# RTS591x register map
Vendor: Realtek Semiconductor Corp.; Series: RTS591x Series; File version: 1.0
CPU: ARMV8MML r0p0, little endian, MPU, FPU, VTOR, 3 interrupt priority bits, 4 SAU regions
Registers are 32-bit, read-write, reset 0x0 unless marked. A register's access mark holds for its fields unless they carry their own. Offsets are from the block's base; [hi:lo] are bit positions; {n}, {i} and the like mark numbered series; 'fields as' and 'values as' point back to an identical list.

## I2C0 — I2C Controller
Base 0x4000D000
Same registers: I2C1 0x4000D200, I2C2 0x4000D400, I2C3 0x4000D600, I2C4 0x4000D800, I2C5 0x4000DA00, I2C6 0x4000DC00, I2C7 0x4000DE00
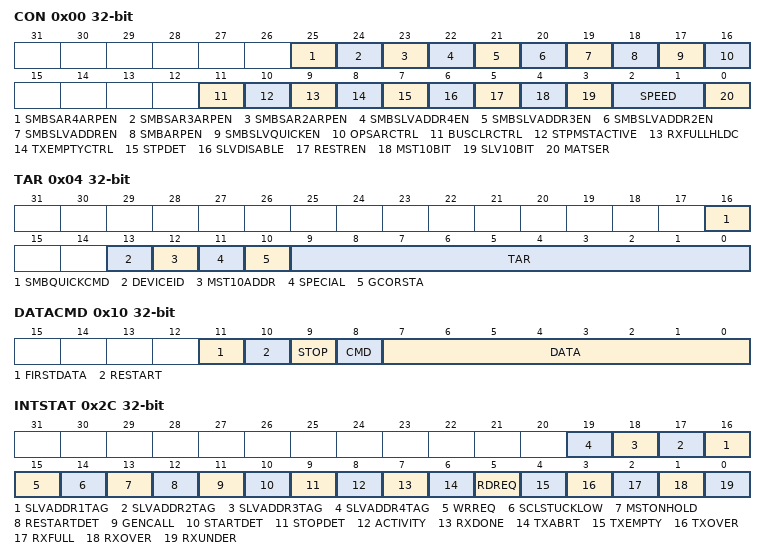
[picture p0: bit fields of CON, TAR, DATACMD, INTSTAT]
0x00 CON — CONTROL REGISTER
  [25] SMBSAR4ARPEN — Enabled ARP Control Or Not
    0=Disable (SMBus ARP control is disabled); 1=Enable (SMBus ARP control is enabled)
  [24] SMBSAR3ARPEN — Enabled ARP Control Or Not
    0=DISABLE (SMBus ARP control is disabled); 1=ENABLE (SMBus ARP control is enabled)
  [23] SMBSAR2ARPEN — Enabled ARP Control Or Not
    values as SMBSAR3ARPEN
  [22] SMBSLVADDR4EN — SMBus Persistent Slave address(SAR4) Control Is Enabled Or Not
    0=DISABLE (SMBus Persistent Slave address(SAR4) control is disabled); 1=ENABLE (SMBus Persistent Slave address(SAR4) control is enabled)
  [21] SMBSLVADDR3EN — SMBus Persistent Slave Address(SAR3) Control Is Enabled Or Not
    0=DISABLE (SMBus Persistent Slave address(SAR3) control is disabled); 1=ENABLE (SMBus Persistent Slave address(SAR3) control is enabled)
  [20] SMBSLVADDR2EN — SMBus Persistent Slave Address(SAR2) Control Is Enabled Or Not
    0=DISABLE (SMBus Persistent Slave address(SAR2) control is disabled); 1=ENABLE (SMBus Persistent Slave address(SAR2) control is enabled)
  [19] SMBSLVADDREN — SMBus Persistent Slave Address Control Is Enabled Or Not
    0=DISABLE (SMBus Persistent Slave address control is disabled); 1=ENABLE (SMBus Persistent Slave address control is enabled)
  [18] SMBARPEN — Enabled ARP Control Or Not
    values as SMBSAR3ARPEN
  [17] SMBSLVQUICKEN — Receive Quick Command Or Not
    0=DISABLE (SMBus Slave is disabled to receive Quick command); 1=ENABLE (SMBus Slave is enabled to receive Quick command)
  [16] OPSARCTRL — Enables the Usage of IC_OPTIONAL_SAR
    0=DISABLE (Optional SAR Address Register is disabled); 1=ENABLE (Optional SAR Address Register is enabled)
  [11] BUSCLRCTRL — Enables the Bus Clear Feature
    0=DISABLE (Bus Clear Feature is enabled); 1=ENABLE (Bus Clear Feature is disabled)
  [10] STPMSTACTIVE — How I2c Controller Issues The Stop Detection Interrupt
    0=DISABLE (Master issues the stop detection interrupt irrespective of whether master is active or not); 1=ENABLE (Master issues the stop detection interrupt only when master is active)
  [9] RXFULLHLDC — Hold the Bus When The Rx FIFO Is Full Or Not
    0=DISABLE (Overflow when RX FIFO is full); 1=ENABLE (Hold bus when RX FIFO is full)
  [8] TXEMPTYCTRL — Controls the Generation Of The Tx Empty Interrupt
    0=DISABLE (Default behaviour of tx empty interrupt); 1=ENABLE (Controlled generation of tx empty interrupt)
  [7] STPDET — How Slave Issues Stop Detection Interrupt
    0=ALWAYS (Slave issues stop detection interrupt always); 1=ADDRESSED (Slave issues stop detection interrupt only if addressed)
  [6] SLVDISABLE — Enable/Disable Slave Mode
    0=Enable slave mode; 1=Disable slave mode
  [5] RESTREN — Enable/Disable Master Restart
    0=DISABLE (Master restart disabled); 1=ENABLE (Master restart enabled)
  [4] MST10BIT — Master Is 7-bit Or 10-bit Addressing Mode
    0=7_BIT (Master 7-bit addressing); 1=10_BIT (Master 10-bit addressing)
  [3] SLV10BIT — Slave Responds To 7-bit Or 10-bit Addresses
    0=7_BIT (Slave 7-bit addressing); 1=10_BIT (Slave 10-bit addressing)
  [2:1] SPEED — Speed Mode
    0=NONE (Not defined); 1=STANDARD (Standard Speed mode of operation); 2=FAST (Fast or Fast Plus mode of operation); 3=HIGH (High Speed mode of operation)
  [0] MATSER — Enable/Disable Master Mode
    0=DISABLE (Master mode is disabled); 1=ENABLE (Master mode is enabled)
0x04 TAR — TARGET ADDRESS REGISTER
  [16] SMBQUICKCMD — Indicates Whether A Quick Command Is To Be Performed
    0=DISABLE (Disables programming of QUICK-CMD transmission); 1=ENABLE (Enables programming of QUICK-CMD transmission)
  [13] DEVICEID — Programming of DEVICE-ID Transmission
    0=DISABLE (Disables programming of DEVICE-ID transmission); 1=ENABLE (Enables programming of DEVICE-ID transmission)
  [12] MST10ADDR — Control Starts Transfers In 7-bit Or 10-bit Addressing Mode
    0=7_BIT (Address 7-bit transmission format); 1=10_BIT (Address 10-bit transmission format)
  [11] SPECIAL — Indicates Whether Software Performs A Device-id Or General Call Or Start Byte Command
    0=DISABLE (Disables programming of GENERAL_CALL or START_BYTE transmission); 1=ENABLE (Enables programming of GENERAL_CALL or START_BYTE transmission)
  [10] GCORSTA — Indicates Whether A General Call Or Start Byte Command
    0=GEN_CALL (General Call byte transmission); 1=START (START byte transmission)
  [9:0] TAR — Target Address For Any Master Transaction
0x08 SAR — SLAVE ADDRESS REGISTER
  [9:0] SAR — Holds The Slave Address When The I2c Is Operating As A Slave
0x0C HSMADDR — HIGH SPEED MASTER MODE CODE ADDRESS REGISTER
  [2:0] HSMAR — Holds The Value Of The I2C HS Mode Master Code
0x10 DATACMD — DATA BUFFER AND COMMAND REGISTER
  [11] FIRSTDATA ro — Indicates The First Data Byte Received After The Address Phase
    0=INACTIVE (Non sequential data byte received); 1=ACTIVE (Sequential data byte received)
  [10] RESTART wo — Controls Whether a RESTART Is Issued Before The Byte Is Sent Or Received
    0=DISABLE (Do not Issue RESTART before this command); 1=ENABLE (Issue RESTART before this command)
  [9] STOP wo — Controls Whether A Stop Is Issued After The Byte Is Sent Or Received
    0=DISABLE (Do not issue STOP after this command); 1=ENABLE (Issue STOP after this command)
  [8] CMD wo — Controls Whether A Read Or A Write Is Performed
    0=WRITE (Master write command); 1=READ (Master read command)
  [7:0] DATA — The Data To Be Transmitted Or Received On The I2C Bus
0x14 SCLHCNT — STANDARD SPEED I2C CLOCK SCL HIGH COUNT REGISTER
  [15:0] HCNT — Sets the SCL Clock High-period Count For Standard Speed
0x14 UFMSCLHCNT (alternate view of SCLHCNT) — ULTRA-FAST SPEED I2C CLOCK SCL HIGH COUNT REGISTER
  [15:0] UFMHCNT — Sets the SCL Clock High-period Count For Ultra-Fast Speed
0x18 SCLLCNT — STANDARD SPEED I2C CLOCK SCL LOW COUNT REGISTER
  [15:0] LCNT — Sets the SCL Clock Low-period Count For Standard Speed
0x18 UFMSCLLCNT (alternate view of SCLLCNT) — ULTRA-FAST I2C CLOCK SCL LOW COUNT REGISTER
  [15:0] UFMLCNT — Sets the SCL Clock Low-period Count For Ultra-Fast Speed
0x1C FSSCLHCNT — FAST MODE SCL HIGH COUNT REGISTER
  [15:0] HCNT — Sets the SCL Clock High-period Count For Fast Speed
0x1C UFMTBUFCNT (alternate view of FSSCLHCNT) — ULTRA-FAST SPEED MODE TBUF IDLE COUNT REGISTER
  [15:0] TBUFCNT — Sets the Bus-Free time between a STOP and STOP condition count for Ultra-Fast speed
0x20 FSSCLLCNT — FAST MODE SCL LOW COUNT REGISTER
  [15:0] LCNT — Sets the SCL Clock Low-period Count For Fast Speed
0x24 HSSCLHCNT — HIGH SPEED SCL HIGH COUNT REGISTER
  [15:0] HCNT — Sets the SCL Clock High-period Count For High Speed
0x28 HSSCLLCNT — HIGH SPEED SCL LOW COUNT REGISTER
  [15:0] LCNT — Sets the SCL clock low-period count for high speed
0x2C INTSTAT ro — I2C INTERRUPT STATUS REGISTER
  [n+15] SLVADDR{n}TAG (n=1..4) — SLV_ADDR{n}_TAG Interrupt
    0=INACTIVE (SLV_ADDR{n}_TAG interrupt is inactive); 1=ACTIVE (SLV_ADDR{n}_TAG interrupt is active)
  [15] WRREQ — WR_REQ Interrupt
    0=INACTIVE (WR_REQ interrupt is inactive); 1=ACTIVE (WR_REQ interrupt is active)
  [14] SCLSTUCKLOW — SCL_STUCK_AT_LOW Interrupt
    0=INACTIVE (SCL_STUCK_AT_LOW interrupt is inactive); 1=ACTIVE (SCL_STUCK_AT_LOW interrupt is active)
  [13] MSTONHOLD — MASTER_ON_HOLD Interrupt
    0=INACTIVE (MASTER_ON_HOLD interrupt is inactive); 1=ACTIVE (MASTER_ON_HOLD interrupt is active)
  [12] RESTARTDET — RESTART_DET Interrupt
    0=INACTIVE (RESTART_DET interrupt is inactive); 1=ACTIVE (RESTART_DET interrupt is active)
  [11] GENCALL — GEN_CALL Interrupt
    0=INACTIVE (GEN-CALL interrupt is inactive); 1=ACTIVE (GEN-CALL interrupt is active)
  [10] STARTDET — START_DET Interrupt
    0=INACTIVE (START_DET interrupt is inactive); 1=ACTIVE (START_DET interrupt is active)
  [9] STOPDET — STOP_DET Interrupt
    0=INACTIVE (STOP_DET interrupt is inactive); 1=ACTIVE (STOP_DET interrupt is active)
  [8] ACTIVITY — ACTIVITY Interrupt
    0=INACTIVE (ACTIVITY interrupt is inactive); 1=ACTIVE (ACTIVITY interrupt is active)
  [7] RXDONE — RX_DONE Interrupt
    0=INACTIVE (RX_DONE interrupt is inactive); 1=ACTIVE (RX_DONE interrupt is active)
  [6] TXABRT — TX_ABRT Interrupt
    0=INACTIVE (TX_ABRT interrupt is inactive); 1=ACTIVE (TX_ABRT interrupt is active)
  [5] RDREQ — RD_REQ interrupt
    0=INACTIVE (RD_REQ interrupt is inactive); 1=ACTIVE (RD_REQ interrupt is active)
  [4] TXEMPTY — TX_EMPTY Interrupt
    0=INACTIVE (TX_EMPTY interrupt is inactive); 1=ACTIVE (TX_EMPTY interrupt is active)
  [3] TXOVER — TX_OVER Interrupt
    0=INACTIVE (TX_OVER interrupt is inactive); 1=ACTIVE (TX_OVER interrupt is active)
  [2] RXFULL — RX_FULL Interrupt
    0=INACTIVE (RX_FULL interrupt is inactive); 1=ACTIVE (RX_FULL interrupt is active)
  [1] RXOVER — RX_OVER Interrupt
    0=INACTIVE (RX_OVER interrupt is inactive); 1=ACTIVE (RX_OVER interrupt is active)
  [0] RXUNDER — RX_UNDER Interrupt
    0=INACTIVE (RX_UNDER interrupt is inactive); 1=ACTIVE (RX_UNDER interrupt is active)
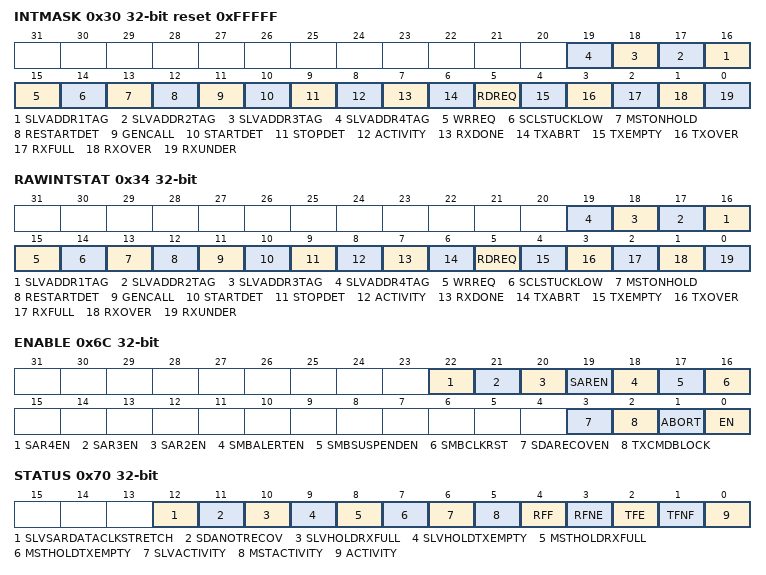
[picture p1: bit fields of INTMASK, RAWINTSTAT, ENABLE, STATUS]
0x30 INTMASK reset 0xFFFFF — INTERRUPT MASK REGISTER
  [n+15] SLVADDR{n}TAG (n=1..4) — SLV_ADDR{n}_TAG Interrupt Mask
    1=UNMASKED (SLV_ADDR{n}_TAG interrupt is unmasked); 0=MASKED (SLV_ADDR{n}_TAG interrupt is masked)
  [15] WRREQ — WR_REQ Interrupt Mask
    1=UNMASKED (WR_REQ interrupt is unmasked); 0=MASKED (WR_REQ interrupt is masked)
  [14] SCLSTUCKLOW — SCL_STUCK_AT_LOW Interrupt Mask
    1=UNMASKED (SCL_STUCK_AT_LOW interrupt is unmasked); 0=MASKED (SCL_STUCK_AT_LOW interrupt is masked)
  [13] MSTONHOLD — MASTER_ON_HOLD Interrupt Mask
    1=UNMASKED (MASTER_ON_HOLD interrupt is unmasked); 0=MASKED (MASTER_ON_HOLD interrupt is masked)
  [12] RESTARTDET — RESTART_DET Interrupt Mask
    1=UNMASKED (RESTART_DET interrupt is unmasked); 0=MASKED (RESTART_DET interrupt is masked)
  [11] GENCALL — GEN_CALL Interrupt Mask
    1=UNMASKED (GEN-CALL interrupt is unmasked); 0=MASKED (GEN-CALL interrupt is masked)
  [10] STARTDET — START_DET Interrupt Mask
    1=UNMASKED (START_DET interrupt is unmasked); 0=MASKED (START_DET interrupt is masked)
  [9] STOPDET — STOP_DET Interrupt Mask
    1=UNMASKED (STOP_DET interrupt is unmasked); 0=MASKED (STOP_DET interrupt is masked)
  [8] ACTIVITY — ACTIVITY Interrupt Mask
    1=UNMASKED (ACTIVITY interrupt is unmasked); 0=MASKED (ACTIVITY interrupt is masked)
  [7] RXDONE — RX_DONE Interrupt Mask
    1=UNMASKED (RX_DONE interrupt is unmasked); 0=MASKED (RX_DONE interrupt is masked)
  [6] TXABRT — TX_ABRT Interrupt Mask
    1=UNMASKED (TX_ABRT interrupt is unmasked); 0=MASKED (TX_ABRT interrupt is masked)
  [5] RDREQ — RD_REQ Interrupt Mask
    1=UNMASKED (RD_REQ interrupt is unmasked); 0=MASKED (RD_REQ interrupt is masked)
  [4] TXEMPTY — TX_EMPTY Interrupt Mask
    1=UNMASKED (TX_EMPTY interrupt is unmasked); 0=MASKED (TX_EMPTY interrupt is masked)
  [3] TXOVER — TX_OVER Interrupt Mask
    1=UNMASKED (TX_OVER interrupt is unmasked); 0=MASKED (TX_OVER interrupt is masked)
  [2] RXFULL — RX_FULL Interrupt Mask
    1=UNMASKED (RX_FULL interrupt is unmasked); 0=MASKED (RX_FULL interrupt is masked)
  [1] RXOVER — RX_OVER Interrupt Mask
    1=UNMASKED (RX_OVER interrupt is unmasked); 0=MASKED (RX_OVER interrupt is masked)
  [0] RXUNDER — RX_UNDER Interrupt Mask
    1=UNMASKED (RX_UNDER interrupt is unmasked); 0=MASKED (RX_UNDER interrupt is masked)
0x34 RAWINTSTAT — INTERRUPT STATUS REGISTER
  [n+15] SLVADDR{n}TAG ro (n=1..4) — SLV_ADDR{n}_TAG Interrupt Status
    values as INTSTAT.SLVADDR1TAG
  [15] WRREQ ro — WR_REQ Interrupt Status
    values as INTSTAT.WRREQ
  [14] SCLSTUCKLOW ro — SCL_STUCK_AT_LOW Interrupt Status
    values as INTSTAT.SCLSTUCKLOW
  [13] MSTONHOLD ro — MASTER_ON_HOLD Interrupt Status
    values as INTSTAT.MSTONHOLD
  [12] RESTARTDET ro — RESTART_DET Interrupt Status
    values as INTSTAT.RESTARTDET
  [11] GENCALL ro — GEN_CALL Interrupt Status
    values as INTSTAT.GENCALL
  [10] STARTDET ro — START_DET Interrupt Status
    values as INTSTAT.STARTDET
  [9] STOPDET ro — STOP_DET Interrupt Status
    values as INTSTAT.STOPDET
  [8] ACTIVITY ro — I2C Controller Activity
    0=INACTIVE (RAW_INTR_ACTIVITY interrupt is inactive); 1=ACTIVE (RAW_INTR_ACTIVITY interrupt is active)
  [7] RXDONE ro — RX_DONE Interrupt Status
    values as INTSTAT.RXDONE
  [6] TXABRT ro — TX_ABRT Interrupt Status
    values as INTSTAT.TXABRT
  [5] RDREQ ro — RD_REQ Interrupt Status
    values as INTSTAT.RDREQ
  [4] TXEMPTY ro — TX_EMPTY Interrupt Status
    values as INTSTAT.TXEMPTY
  [3] TXOVER ro — TX_OVER Interrupt Status
    values as INTSTAT.TXOVER
  [2] RXFULL ro — RX_UNDER Interrupt Status
    values as INTSTAT.RXFULL
  [1] RXOVER ro — RX_UNDER Interrupt Status
    values as INTSTAT.RXOVER
  [0] RXUNDER ro — RX_UNDER Interrupt Status
    values as INTSTAT.RXUNDER
0x38 RXTL — I2C RECEIVE FIFO THRESHOLD REGISTER
  [7:0] THRES — Receive FIFO Threshold Level
0x3C TXTL — I2C TRANSMIT FIFO THRESHOLD REGISTER
  [7:0] THRES — Transmit FIFO Threshold Level
0x40 CLRINT ro — CLEAR COMBINED AND INDIVIDUAL INTERRUPT REGISTER
0x44 CLRRXUNDER ro — Clear RX_UNDER Interrupt
0x48 CLRRXOVER ro — Clear RX_OVER Interrupt Register
0x4C CLRTXOVER ro — Clear TX_OVER Interrupt Register
0x50 CLRRDREQ ro — Clear RD_REQ Interrupt Register
0x54 CLRTXABRT ro — Clear TX_ABRT Interrupt Register
0x58 CLRRXDONE ro — Clear RX_DONE Interrupt Register
0x5C CLRACTIVITY ro — Clear ACTIVITY Interrupt Register
0x60 CLRSTOPDET ro — Clear STOP_DET Interrupt Register
0x64 CLRSTARTDET ro — Clear START_DET Interrupt Register
0x68 CLRGENCALL ro — Clear GEN_CALL Interrupt Register
0x6C ENABLE
  [22] SAR4EN — Controls Whether the SAR4 is Enabled
    0=DISABLE (SAR4 is disabled); 1=ENABLE (SAR4 is enabled)
  [21] SAR3EN — Controls Whether the SAR3 is Enabled
    0=DISABLE (SAR3 is disabled); 1=ENABLE (SAR3 is enabled)
  [20] SAR2EN — Controls Whether the SAR2 is Enabled
    0=DISABLE (SAR2 is disabled); 1=ENABLE (SAR2 is enabled)
  [19] SAREN — Controls Whether the SAR is Enabled
    0=DISABLE (SAR is disabled); 1=ENABLE (SAR is enabled)
  [18] SMBALERTEN — Control Assertion of SMBALERT Signal
    0=DISABLE (Slave will not initates the Alert signal to indicate SMBus Host.); 1=ENABLE (Slave initates the Alert signal to indicate SMBus Host)
  [17] SMBSUSPENDEN — SMBSUS Suspend Mode
    0=DISABLE (Host/Master will not initates the SMBUS system to enter Suspend Mode); 1=ENABLE (Host/Master initates the SMBUS system to enter Suspend Mode)
  [16] SMBCLKRST — SMBus Master Clock Reset
    0=DISABLE (Master will not initates SMBUS Clock Reset Mechanism); 1=ENABLE (Master initates the SMBUS Clock Reset Mechanism)
  [3] SDARECOVEN — Control Knob To Initiate The SDA Recovery Mechanism
    0=DISABLE (Master disabled the SDA stuck at low recovery mechanism); 1=ENABLE (Master initiates the SDA stuck at low recovery mechanism)
  [2] TXCMDBLOCK — Blocks The Transmission Of Data On I2c Bus Or Not
    0=DISABLE (The transmission of data starts on I2C bus automatically); 1=ENABLE (Blocks the transmission of data on I2C bus even if Tx FIFO has data to transmit)
  [1] ABORT — Initiates The Transfer Abort
    0=DISABLE (ABORT operation not in progress); 1=ENABLE (ABORT operation in progress)
  [0] EN — Controls Whether The I2C Controller Is Enabled
    0=DISABLE (Disables I2C controller); 1=ENABLE (Enable I2C controller)
0x70 STATUS ro — I2C STATUS Register
  [12] SLVSARDATACLKSTRETCH — Indicates The Bus Hold (clock Stretching) In Slave Mode With Multiple SAR Feature
    0=Inactive (Slave is not holding the bus to isolate current RX FIFO data from next transfer related to another slave address); 1=Active (Slave holds the bus to isolate current RX FIFO data from next transfer related to another slave address)
  [11] SDANOTRECOV — Indicates That SDA Stuck At Low Is Not Recovered After The Recovery Mechanism
    0=Inactive (SDA Stuck at low is recovered after recovery mechanism); 1=Active (SDA Stuck at low is not recovered after recovery mechanism)
  [10] SLVHOLDRXFULL — Indicates The Bus Hold In Slave Mode Due To Rx FIFO Is Full And Additional Byte Has Been Received
    0=Inactive (Slave is not holding the bus or Bus hold is not due to Rx FIFO is full); 1=Active (Slave holds the bus due to Rx FIFO is full)
  [9] SLVHOLDTXEMPTY — Indicates The Bus Hold In Slave Mode Due To Rx FIFO Is Full And Additional Byte Has Been Received
    0=INACTIVE (Slave is not holding the bus or Bus hold is not due to Rx FIFO is full); 1=ACTIVE (Slave holds the bus due to Rx FIFO is full)
  [8] MSTHOLDRXFULL — INdicates The Bus Hold In Master Mode Due To Rx FIFO Is Full And Additional Byte Has Been Received
    0=INACTIVE (Master is not holding the bus or Bus hold is not due to Rx FIFO is full); 1=ACTIVE (Master holds the bus due to Rx FIFO is full)
  [7] MSTHOLDTXEMPTY — Indicates The Bus Hold When The Master Holds The Bus Because Of The Tx FIFO Being Empty
    0=INACTIVE (Master holds the bus due to Tx FIFO is empty); 1=ACTIVE (Master is not holding the bus or Bus hold is not due to Tx FIFO is empty)
  [6] SLVACTIVITY — Slave FSM Activity Status
    0=IDLE (Slave is idle); 1=ACTIVE (Slave not idle)
  [5] MSTACTIVITY — Master FSM Activity Status
    0=IDLE (Master is idle); 1=ACTIVE (Master not idle)
  [4] RFF — Receive FIFO Completely Full
    0=NOTFULL (Rx FIFO not full); 1=FULL (Rx FIFO is full)
  [3] RFNE — Receive FIFO Not Empty
    0=EMPTY (Rx FIFO is empty); 1=NOTEMPTY (Rx FIFO not empty)
  [2] TFE — Transmit FIFO Completely Empty
    0=NOTEMPTY (Tx FIFO not empty); 1=EMPTY (Tx FIFO is empty)
  [1] TFNF — Transmit FIFO Not Full
    0=FULL (Tx FIFO is full); 1=NOTFULL (Tx FIFO not full)
  [0] ACTIVITY — I2C Activity Status
    0=INACTIVE (I2C is idle); 1=ACTIVE (I2C is active)
0x74 TXFLR — I2C TRANSMIT FIFO LEVEL REGISTER
0x78 RXFLR — I2C RECEIVE FIFO LEVEL REGISTER
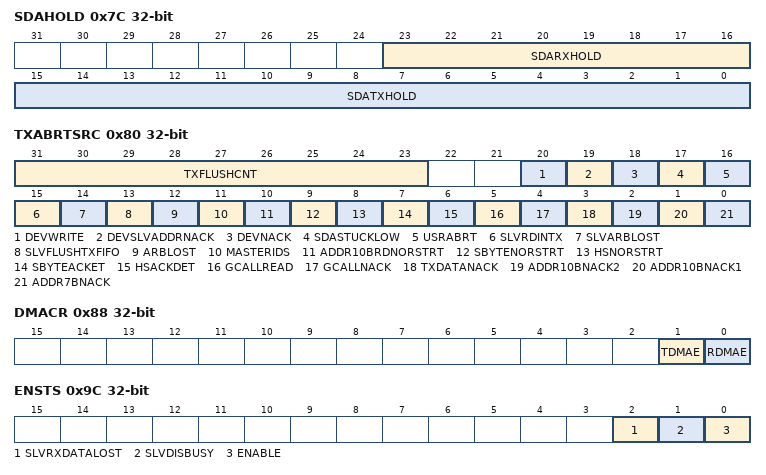
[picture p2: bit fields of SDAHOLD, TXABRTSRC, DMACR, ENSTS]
0x7C SDAHOLD — I2C SDA HOLD TIME LENGTH REGISTER
  [23:16] SDARXHOLD — Sets the required SDA hold time in units of I2C clk period
  [15:0] SDATXHOLD — Sets The Required SDA Hold Time In Units Of clk Period
0x80 TXABRTSRC — I2C TRANSMIT ABORT SOURCE REGISTER
  [31:23] TXFLUSHCNT ro — Indicates The Number Of Tx FIFO Data Commands Which Are Flushed Due To TX_ABRT Interrupt
  [20] DEVWRITE ro — Master Is Initiating The DEVICE_ID Transfer And The Tx-FIFO Consists Of Write Commands
    0=NOTABORT (This abort is not generated); 1=ABORT (This abort is generated because of NOACK for Slave address)
  [19] DEVSLVADDRNACK ro — Master Is Initiating The DEVICE_ID Transfer And The Slave Address Sent Was Not Acknowledged By Any Slave
    values as DEVWRITE
  [18] DEVNACK ro — Master Is Initiating The DEVICE_ID Transfer And The Device Id Sent Was Not Acknowledged By Any Slave
    0=NOTABORT (This abort is not generated); 1=ABORT (This abort is generated because of NOACK for DEVICE-ID)
  [17] SDASTUCKLOW ro — This Is A Master-mode-only Bit. Master Detects The SDA Stuck At Low
    0=NOTABORT (This abort is not generated); 1=ABORT (This abort is generated because of SDA stuck at low)
  [16] USRABRT ro — This Is A Master-mode-only Bit. Master Has Detected The Transfer Abort
    0=NOTABORT (Transfer abort detected by master- scenario not present); 1=ABORT (Transfer abort detected by master)
  [15] SLVRDINTX ro — When The Processor Side Responds To A Slave Mode Request For Data To Be Transmitted To A Remote Master And User Writes A 1 In Cmd (bit 8) Of Ic_data_cmd Register
    0=NOTABORT (Slave trying to transmit to remote master in read mode- scenario not present); 1=ABORT (Slave trying to transmit to remote master in read mode)
  [14] SLVARBLOST ro — This Field Indicates That A Slave Has Lost The Bus While Transmitting Data To A Remote Master
    0=NOTLOST (Slave lost arbitration to remote master- scenario not present); 1=LOST (Slave lost arbitration to remote master)
  [13] SLVFLUSHTXFIFO ro — This Field Specifies That The Slave Has Received A Read Command And Some Data Exists In The TX FIFO
    0=NONABORT (Slave flushes existing data in TX-FIFO upon getting read commandscenario not present); 1=ABORT (Slave flushes existing data in TX-FIFO upon getting read command)
  [12] ARBLOST ro — This Field Specifies That The Master Has Lost Arbitration
    0=NOTLOST (Master or Slave-Transmitter lost arbitration- scenario not present); 1=LOST (Master or Slave-Transmitter lost arbitration)
  [11] MASTERIDS ro — Indicates That The User Tries To Initiate A Master Operation With The Master Mode Disabled
    0=NONABORT (User initiating master operation when MASTER disabled- scenario not present); 1=ABORT (User initiating master operation when MASTER disabled)
  [10] ADDR10BRDNORSTRT ro — Indicates That The Restart Is Disabled
    0=NONABORT (Master not trying to read in 10Bit addressing mode when RESTART disabled); 1=ABORT (Master trying to read in 10Bit addressing mode when RESTART disabled)
  [9] SBYTENORSTRT ro — Indicates That The Restart Is Disabled
    0=NONABORT (User trying to send START byte when RESTART disabled- scenario not present); 1=ABORT (User trying to send START byte when RESTART disabled)
  [8] HSNORSTRT ro — Indicates That The Restart Is Disabled
    0=NONABORT (User trying to switch Master to HS mode when RESTART disabled- scenario not present); 1=ABORT (User trying to switch Master to HS mode when RESTART disabled)
  [7] SBYTEACKET ro — Indicates That The Master Has Sent A START Byte And The START Byte Was Acknowledged
    0=NACK (ACK detected for START byte- scenario not present); 1=ACK (ACK detected for START byte)
  [6] HSACKDET ro — Indicates That The Master Is In High Speed Mode And The High Speed Master Code Was Acknowledged
    0=NACK (HS Master code ACKed in HS Mode- scenario not present); 1=ACK (HS Master code ACKed in HS Mode)
  [5] GCALLREAD ro — Indicates That Dw_apb_i2c In The Master Mode Has Sent A General Call But The User Programmed The Byte Following The General Call To Be A Read From The Bus
    0=NONABORT (GCALL is followed by read from bus-scenario not present); 1=ABORT (GCALL is followed by read from bus)
  [4] GCALLNACK ro — Indicates That I2C Controller In Master Mode Has Sent A General Call And No Slave On The Bus Acknowledged The General Call
    0=NACK (GCALL not ACKed by any slave-scenario not present); 1=ACK (GCALL not ACKed by any slave)
  [3] TXDATANACK ro — Indicates The Master-mode Only Bit. When Themaster Receives An Acknowledgement For The Address
    0=NACK (Transmitted data non-ACKed by addressed slave-scenario not present); 1=ACK (Transmitted data not ACKed by addressed slave)
  [2] ADDR10BNACK2 ro — Indicates That The Master Is In 10-bit Address Mode And The Second 10-bit Address Byte Was Not Acknowledged By Any Slave
    0=INACTIVE (This abort is not generated); 1=ACTIVE (Byte 2 of 10Bit Address not ACKed by any slave)
  [1] ADDR10BNACK1 ro — Indicates That The Master Is In 10-bit Address Mode And The First 10-bit Address Byte Was Not Acknowledged By Any Slave
    0=INACTIVE (This abort is not generated); 1=ACTIVE (Byte 1 of 10Bit Address not ACKed by any slave)
  [0] ADDR7BNACK ro — Indicates That The Master Is In 7-bit Addressing Mode And The Address Sent Was Not Acknowledged By Any Slave
    0=INACTIVE (This abort is not generated); 1=ACTIVE (This abort is generated because of NOACK for 7-bit address)
0x84 SLVDATANACKONLY — GENERATE SLAVE DATA NACK REGISTER
  [0] NACK — Generate Nack. This Nack Generation Only Occurs When I2C Controller Is A Slave-receiver
    0=DISABLE (Slave receiver generates NACK normally); 1=ENABLE (Slave receiver generates NACK upon data reception only)
0x88 DMACR — DMA CONTROL REGISTER
  [1] TDMAE — Transmit DMA Enable
    0=DISABLE (Transmit FIFO DMA channel disabled); 1=ENABLE (Transmit FIFO DMA channel enabled)
  [0] RDMAE — Receive DMA Enable
    0=DISABLE (Receive FIFO DMA channel disabled); 1=ENABLE (Receive FIFO DMA channel enabled)
0x8C DMATDLR — DMA Transmit Data Level Register
0x90 DMARDLR — DMA RECEIVE DATA LEVEL REGISTER
0x94 SDASETUP — I2C SDA SETUP REGISTER
  [7:0] SETUP — SDA Setup (tSU:DAT)
0x98 ACKGENCALL — I2C ACK GENERAL CALL REGISTER
  [0] ACK — ACK General Call
    0=NACK (Generate NACK for General Call); 1=ACK (Generate ACK for a General Call)
0x9C ENSTS ro — I2C ENABLE STATUS REGISTER
  [2] SLVRXDATALOST — Slave Received Data Lost
    0=DISABLE (Slave RX Data is not lost); 1=ENABLE (Slave RX Data is lost)
  [1] SLVDISBUSY — Slave Disabled While Busy (Transmit, Receive)
    0=DISABLE (Slave is disabled when it is idle); 1=ENABLE (Slave is disabled when it is active)
  [0] ENABLE — IC Enable Status
    0=DISABLE (I2C disabled); 1=ENABLE (I2C enabled)
0xA0 SPKLEN — I2C SS, FS OR FM+ RO UFM SPIKE SUPPRESSION LIMIT
  [7:0] LEN — Sets the Duration, Measured In Clk Cycle
0xA4 HSSPKLEN — I2C HS SPIKE SUPPRESSION LIMIT REGISTER
  [7:0] LEN — Sets the duration, measured in clk cycle
0xA8 CLRRESTARTDET — CLEAR RESTART_DET INTERRUPT REGISTER
0xAC SCLLOWTO — I2C SCL STUCK AT LOW TIMEOUT REGISTER
0xB0 SDALOWTO — I2C SDA STUCK AT LOW TIMEOUT REGISTER
0xB4 CLRSCLSTUCKDET — CLEAR SCL STUCK AT LOW DETECT INTERRUPT REGISTER
0xB8 DEVICEID ro — I2C DEVICE-ID REGISTERS
  [23:0] ID — Contains the Device-ID of the component
0xBC SMBCLKLOWSEXT — SMBUS SLAVE CLOCK EXTEND TIMEOUT REGISTER
0xC0 SMBCLKLOWMEXT — SMBUS MASTER CLOCK EXTEND TIMEOUT REGISTER
0xC4 SMBTHIGHMAXIDLECNT — SMBUS MASTER THIGH MAX BUS-IDLE COUNT REGISTER
  [15:0] CNT — Set The Required Bus-idle Time Period
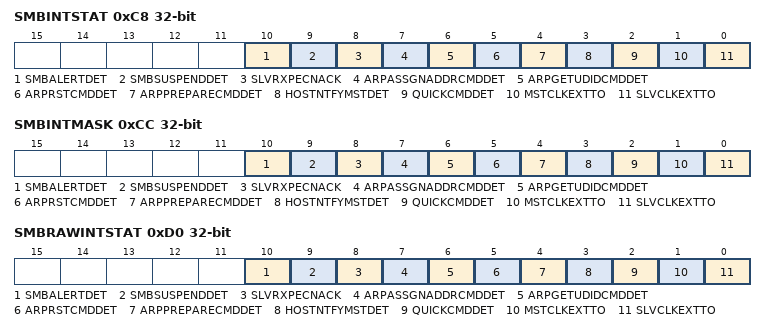
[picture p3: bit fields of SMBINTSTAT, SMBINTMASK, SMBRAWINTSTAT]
0xC8 SMBINTSTAT — SMBUS INTERRUPT STATUS REGISTER
  [10] SMBALERTDET ro — See SMRAWINTSTAT for detail
    0=INACTIVE (SMBUS Alert interrupt is inactive); 1=ACTIVE (SMBUS Alert interrupt is active)
  [9] SMBSUSPENDDET ro — See SMRAWINTSTAT for detail
    0=INACTIVE (SMBUS System Suspended interrupt is inactive); 1=ACTIVE (SMBUS System Suspended interrupt is active)
  [8] SLVRXPECNACK ro — See SMRAWINTSTAT for detail
    0=INACTIVE (SLV_RX_PEC_NACK interrupt is inactive); 1=ACTIVE (SLV_RX_PEC_NACK interrupt is active)
  [7] ARPASSGNADDRCMDDET ro — See SMRAWINTSTAT for detail
    0=INACTIVE (ARP_ASSGN_ADDR_CMD_DET interrupt is inactive); 1=ACTIVE (ARP_ASSGN_ADDR_CMD_DET interrupt is active)
  [6] ARPGETUDIDCMDDET ro — See SMRAWINTSTAT for detail
    0=INACTIVE (ARP_GET_UDID_CMD_DET interrupt is inactive); 1=ACTIVE (ARP_GET_UDID_CMD_DET interrupt is active)
  [5] ARPRSTCMDDET ro — See SMRAWINTSTAT for detail
    0=INACTIVE (ARP_RST_CMD_DET interrupt is inactive); 1=ACTIVE (ARP_RST_CMD_DET interrupt is active)
  [4] ARPPREPARECMDDET ro — See SMRAWINTSTAT for detail
    0=INACTIVE (ARP_PREPARE_CMD_DET interrupt is inactive); 1=ACTIVE (ARP_PREPARE_CMD_DET interrupt is active)
  [3] HOSTNTFYMSTDET ro — See SMRAWINTSTAT for detail
    0=INACTIVE (HOST_NTFY_MST_DET interrupt is inactive); 1=ACTIVE (HOST_NTFY_MST_DET interrupt is active)
  [2] QUICKCMDDET ro — See SMRAWINTSTAT for detail
    0=INACTIVE (Quick Command interrupt is inactive); 1=ACTIVE (Quick Command interrupt is active)
  [1] MSTCLKEXTTO ro — See SMRAWINTSTAT For Detail
    0=INACTIVE (Mater Clock Extend Timeout interrupt is inactive); 1=ACTIVE (Mater Clock Extend Timeout interrupt is active)
  [0] SLVCLKEXTTO ro — See SMRAWINTSTAT For Detail
    0=INACTIVE (Slave Clock Extend Timeout interrupt is inactive); 1=ACTIVE (Slave Clock Extend Timeout interrupt is active)
0xCC SMBINTMASK — SMBUS INTERRUPT MASK REGISTER
  [10] SMBALERTDET — See SMRAWINTSTAT for detail
    0=UNMASKED (SMBUS Alert interrupt is unmasked); 1=MMASKEDasked (SMBUS Alert interrupt is masked)
  [9] SMBSUSPENDDET — See SMRAWINTSTAT for detail
    0=UNMASKED (SMBUS System Suspended interrupt is unmasked); 1=MASKED (SMBUS System Suspended interrupt is masked)
  [8] SLVRXPECNACK — See SMRAWINTSTAT for detail
    0=UNMASKED (SLV_RX_PEC_NACK interrupt is unmasked); 1=MASKED (SLV_RX_PEC_NACK interrupt is masked)
  [7] ARPASSGNADDRCMDDET — See SMRAWINTSTAT for detail
    0=UNMASKED (ARP_ASSGN_ADDR_CMD_DET interrupt is unmasked); 1=MASKED (ARP_ASSGN_ADDR_CMD_DET interrupt is masked)
  [6] ARPGETUDIDCMDDET — See SMRAWINTSTAT for detail
    0=UNMASKED (ARP_GET_UDID_CMD_DET interrupt is unmasked); 1=MASKED (ARP_GET_UDID_CMD_DET interrupt is masked)
  [5] ARPRSTCMDDET — See SMRAWINTSTAT for detail
    0=UNMASKED (ARP_RST_CMD_DET interrupt is unmasked); 1=MASKED (ARP_RST_CMD_DET interrupt is masked)
  [4] ARPPREPARECMDDET — See SMRAWINTSTAT for detail
    0=UNMASKED (ARP_PREPARE_CMD_DET interrupt is unmasked); 1=MASKED (ARP_PREPARE_CMD_DET interrupt is masked)
  [3] HOSTNTFYMSTDET — See SMRAWINTSTAT for detail
    0=UNMASKED (HOST_NTFY_MST_DET interrupt is unmasked); 1=MASKED (HOST_NTFY_MST_DET interrupt is masked)
  [2] QUICKCMDDET — See SMRAWINTSTAT for detail
    0=UNMASKED (Quick Command interrupt is unmasked); 1=MASKED (Quick Command interrupt is masked)
  [1] MSTCLKEXTTO — See SMRAWINTSTAT for detail
    0=UNMASKED (Mater Clock Extend Timeout interrupt is unmasked); 1=MASKED (Mater Clock Extend Timeout interrupt is masked)
  [0] SLVCLKEXTTO — See SMRAWINTSTAT for detail
    0=UNMASKED (Slave Clock Extend Timeout interrupt is unmasked); 1=MASKED (Slave Clock Extend Timeout interrupt is masked)
0xD0 SMBRAWINTSTAT ro — SMBUS RAW INTERRUPT STATUS REGISTER
  [10] SMBALERTDET — Indicates whether a SMBALERT signal is driven low by the slave
    values as SMBINTSTAT.SMBALERTDET
  [9] SMBSUSPENDDET — Indicates whether a SMBSUS signal is driven low by the Host
    values as SMBINTSTAT.SMBSUSPENDDET
  [8] SLVRXPECNACK — Indicates whether a NACK has been sent due to PEC mismatch while working as ARP slave
    values as SMBINTSTAT.SLVRXPECNACK
  [7] ARPASSGNADDRCMDDET — Indicates Whether An Assign Address ARP Command Has Been Received
    values as SMBINTSTAT.ARPASSGNADDRCMDDET
  [6] ARPGETUDIDCMDDET — Indicates Whether a Get UDID ARP Command Has Been Received
    values as SMBINTSTAT.ARPGETUDIDCMDDET
  [5] ARPRSTCMDDET — Indicates Whether A General or Directed Reset ARP Command Has Been Received
    values as SMBINTSTAT.ARPRSTCMDDET
  [4] ARPPREPARECMDDET — Indicates Whether A Prepare To ARP Command Has Been Received
    values as SMBINTSTAT.ARPPREPARECMDDET
  [3] HOSTNTFYMSTDET — Indicates Whether A Notify ARP Master ARP Command Has Been Received
    values as SMBINTSTAT.HOSTNTFYMSTDET
  [2] QUICKCMDDET — Indicates Whether A Quick Command Has Been Received On The SMBus Interface
    values as SMBINTSTAT.QUICKCMDDET
  [1] MSTCLKEXTTO — Indicates Whether The Transaction From Mater
    values as SMBINTSTAT.MSTCLKEXTTO
  [0] SLVCLKEXTTO — Activeindicates Whether The Transaction From Slave
    values as SMBINTSTAT.SLVCLKEXTTO
0xD4 CLRSMBINT — CLEAR SMBUS INTERRUPT REGISTER
0xD8 OPSAR — I2C OPTIONAL SLAVE ADDRESS REGISTER
  [6:0] SAR — Optional Slave Address For I2C Controller When Operating As A Slave In SMBus Mode
{0xDC+4i} SMBUDIDW{i} (i=0..3) — SMBUS ARP UDID WORD{i} REGISTER
0xF0 REGTORST — REGISTER TIMEOUT COUNTER RESET VALUE
0xF4 COMPPARAM1 — COMPONENT PARAMETER REGISTER 1
0xF8 COMPVER — I2C COMPONENT VERSION REGISTER
0xFC COMPTYPE — I2C COMPONENT TYPE REGISTER
{0xF8+4i} SAR{i} (i=2..4) — I2C SLAVE ADDRESS REGISTER {i}
  [9:0] SAR — Slave Address For I2C Controller When Operating As A Slave In SMBus Mode
0x11C CLRWRREQ ro — CLEAR WR_REQ INTERRUPT REGISTER
0x120 CLRSLVADDRTAG ro — CLEAR CLR_SLV_ADDR_TAG INTERRUPT REGISTER
{0x124+4i} SAR2SMBUDIDW{i} (i=0..3) — SAR2 SMBUS ARP UDID WORD{i} REGISTER
{0x134+4i} SAR3SMBUDIDW{i} (i=0..3) — SAR3 SMBUS ARP UDID WORD{i} REGISTER
{0x144+4i} SAR4SMBUDIDW{i} (i=0..3) — SAR4 SMBUS ARP UDID WORD{i} REGISTER
